# GD32M53x register map
File version: 1.0
CPU: CM33 r2p1, little endian, MPU, FPU, DSP, 4 interrupt priority bits
Registers are 32-bit, read-write, reset 0x0 unless marked. A register's access mark holds for its fields unless they carry their own. Offsets are from the block's base; [hi:lo] are bit positions; {n}, {i} and the like mark numbered series.

## RCU — Reset and clock unit
Base 0x40021000
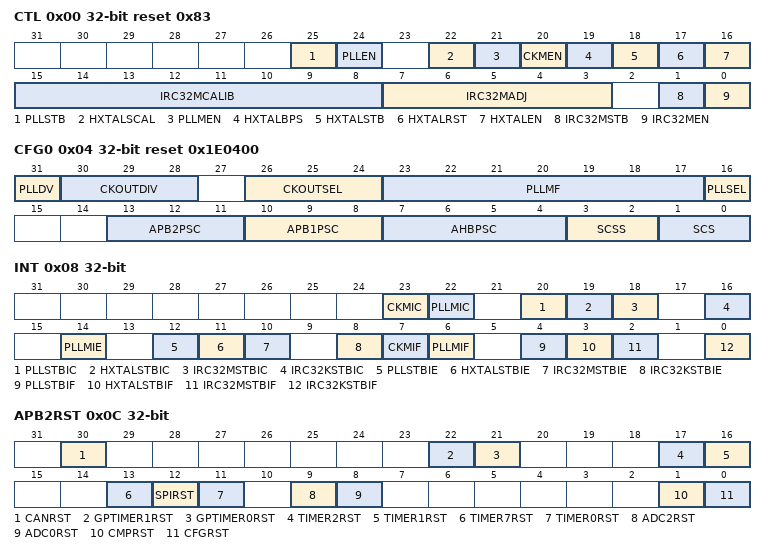
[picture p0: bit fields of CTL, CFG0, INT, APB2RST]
0x00 CTL access per field reset 0x83 — Control register
  [25] PLLSTB ro — PLL clock stabilization flag
  [24] PLLEN rw — PLL enable
  [22] HXTALSCAL rw — HXTAL frequency scale select
  [21] PLLMEN rw — PLL clock monitor enable
  [20] CKMEN rw — HXTAL clock monitor enable
  [19] HXTALBPS rw — External crystal oscillator (HXTAL) clock bypass mode enable
  [18] HXTALSTB ro — External crystal oscillator (HXTAL) clock stabilization flag
  [17] HXTALRST rw — External high speed oscillator ready reset
  [16] HXTALEN rw — External high speed oscillator enable
  [15:8] IRC32MCALIB ro — Internal 32M RC oscillator calibration value register
  [7:3] IRC32MADJ rw — Internal 32M RC oscillator clock trim adjust value
  [1] IRC32MSTB ro — IRC32M high speed internal oscillator stabilization flag
  [0] IRC32MEN rw — Internal high speed oscillator enable
0x04 CFG0 access per field reset 0x1E0400 — Configuration register 0
  [31] PLLDV rw — The CK_PLL divide by 1 or 8 for CK_OUT
  [30:28] CKOUTDIV rw — The CK_OUT divider which the CK_OUT frequency can be reduced, see bits 26:24 of RCU_CFG0 for CK_OUT.
  [26:24] CKOUTSEL rw — CK_OUT clock source selection
  [23:17] PLLMF rw — PLL multiply factor
  [16] PLLSEL rw — PLL clock source selection
  [13:11] APB2PSC rw — APB2 prescaler selection
  [10:8] APB1PSC rw — APB1 prescaler selection
  [7:4] AHBPSC rw — AHB prescaler selection
  [3:2] SCSS ro — System clock switch status
  [1:0] SCS rw — System clock switch
0x08 INT access per field — Interrupt register
  [23] CKMIC wo — HXTAL clock stuck interrupt clear
  [22] PLLMIC wo — PLL clock monitor interrupt clear
  [20] PLLSTBIC wo — PLL stabilization interrupt clear
  [19] HXTALSTBIC wo — HXTAL stabilization interrupt clear
  [18] IRC32MSTBIC wo — IRC32M stabilization interrupt clear
  [16] IRC32KSTBIC wo — IRC32K stabilization interrupt clear
  [14] PLLMIE rw — PLL clock monitor interrupt enable
  [12] PLLSTBIE rw — PLL stabilization interrupt enable
  [11] HXTALSTBIE rw — HXTAL stabilization interrupt enable
  [10] IRC32MSTBIE rw — IRC32M stabilization interrupt enable
  [8] IRC32KSTBIE rw — IRC32K stabilization interrupt enable
  [7] CKMIF ro — HXTAL clock stuck interrupt flag
  [6] PLLMIF ro — PLL clock monitor interrupt flag
  [4] PLLSTBIF ro — PLL stabilization interrupt flag
  [3] HXTALSTBIF ro — HXTAL stabilization interrupt flag
  [2] IRC32MSTBIF ro — IRC32M stabilization interrupt flag
  [0] IRC32KSTBIF ro — IRC32K stabilization interrupt flag
0x0C APB2RST — APB2 reset register
  [30] CANRST — CAN reset
  [22] GPTIMER1RST — GPTIMER1 reset
  [21] GPTIMER0RST — GPTIMER0 reset
  [17] TIMER2RST — TIMER2 reset
  [16] TIMER1RST — TIMER1 reset
  [13] TIMER7RST — TIMER7 reset
  [12] SPIRST — SPI reset
  [11] TIMER0RST — TIMER0 reset
  [9] ADC2RST — ADC2 reset
  [8] ADC0RST — ADC0 reset
  [1] CMPRST — Comparator reset
  [0] CFGRST — System configuration reset
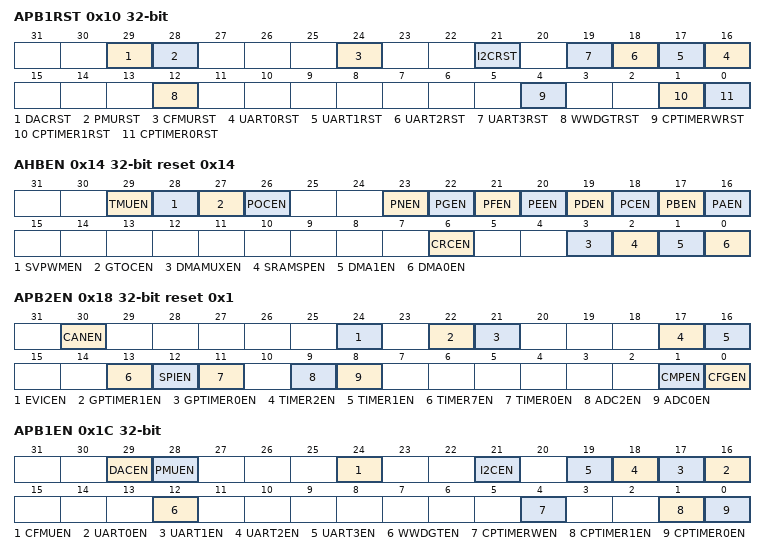
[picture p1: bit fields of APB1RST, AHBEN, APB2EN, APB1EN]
0x10 APB1RST — APB1 reset register
  [29] DACRST — DAC reset
  [28] PMURST — Power control reset
  [24] CFMURST — CFMU reset
  [21] I2CRST — I2C reset
  [n+16] UART{n}RST (n=0..3) — UART{n} reset
  [12] WWDGTRST — Window watchdog timer reset
  [4] CPTIMERWRST — CPTIMERW timer reset
  [1] CPTIMER1RST — CPTIMER1 timer reset
  [0] CPTIMER0RST — CPTIMER0 timer reset
0x14 AHBEN reset 0x14 — AHB enable register
  [29] TMUEN — TMU clock enable
  [28] SVPWMEN — SVPWM clock enable
  [27] GTOCEN — GTOC clock enable
  [26] POCEN — POC clock enable
  [23] PNEN — GPIO port N clock enable
  [22] PGEN — GPIO port G clock enable
  [21] PFEN — GPIO port F clock enable
  [20] PEEN — GPIO port E clock enable
  [19] PDEN — GPIO port D clock enable
  [18] PCEN — GPIO port C clock enable
  [17] PBEN — GPIO port B clock enable
  [16] PAEN — GPIO port A clock enable
  [6] CRCEN — CRC clock enable
  [3] DMAMUXEN — DMAMUX clock enable
  [2] SRAMSPEN — SRAM interface clock enable
  [1] DMA1EN — DMA1 clock enable
  [0] DMA0EN — DMA0 clock enable
0x18 APB2EN reset 0x1 — APB2 enable register
  [30] CANEN — CAN clock enable
  [24] EVICEN — EVIC clock enable
  [22] GPTIMER1EN — GPTIMER1 timer clock enable
  [21] GPTIMER0EN — GPTIMER0 timer clock enable
  [17] TIMER2EN — TIMER2 timer clock enable
  [16] TIMER1EN — TIMER1 timer clock enable
  [13] TIMER7EN — TIMER7 timer clock enable
  [12] SPIEN — SPI clock enable
  [11] TIMER0EN — TIMER0 timer clock enable
  [9] ADC2EN — ADC2 interface clock enable
  [8] ADC0EN — ADC interface clock enable
  [1] CMPEN — Comparator clock enable
  [0] CFGEN — System configuration clock enable
0x1C APB1EN — APB1 enable register
  [29] DACEN — DAC clock enable
  [28] PMUEN — Power interface clock enable
  [24] CFMUEN — CFMU clock enable
  [21] I2CEN — I2C clock enable
  [n+16] UART{n}EN (n=0..3) — UART{n} clock enable
  [12] WWDGTEN — Window watchdog timer clock enable
  [4] CPTIMERWEN — CPTIMERW timer clock enable
  [1] CPTIMER1EN — CPTIMER1 timer clock enable
  [0] CPTIMER0EN — CPTIMER0 timer clock enable
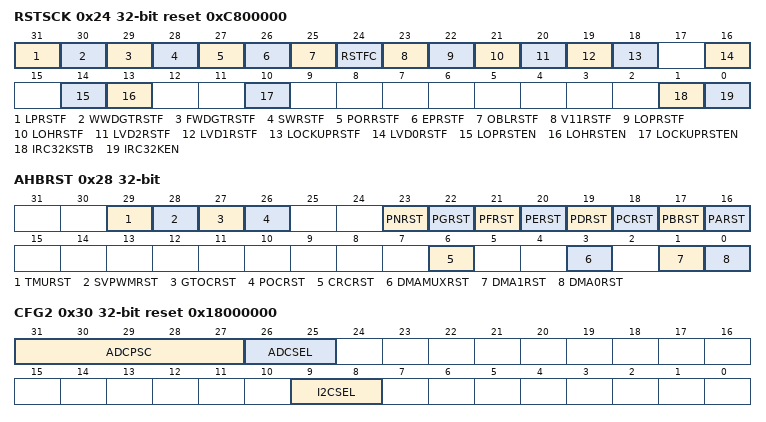
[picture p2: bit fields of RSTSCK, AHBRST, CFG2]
0x24 RSTSCK access per field reset 0xC800000 — Reset source/clock register
  [31] LPRSTF ro — Low-power reset flag
  [30] WWDGTRSTF ro — Window watchdog timer reset flag
  [29] FWDGTRSTF ro — Free Watchdog timer reset flag
  [28] SWRSTF ro — Software reset flag
  [27] PORRSTF ro — Power reset flag
  [26] EPRSTF ro — External PIN reset flag
  [25] OBLRSTF ro — Option byte loader reset flag
  [24] RSTFC rw — Reset flag clear
  [23] V11RSTF ro — 1.1V domain power reset flag
  [22] LOPRSTF ro — Lost of PLL error reset flag
  [21] LOHRSTF ro — Lost of HXTAL error reset flag
  [20] LVD2RSTF ro — Low voltage 2 detect error reset flag
  [19] LVD1RSTF ro — Low voltage 1 detect error reset flag
  [18] LOCKUPRSTF ro — CPU Lock-Up error reset flag
  [16] LVD0RSTF ro — Low voltage 0 detect error reset flag
  [14] LOPRSTEN rw — Lost of PLL reset enable
  [13] LOHRSTEN rw — Lost of HXTAL reset enable
  [10] LOCKUPRSTEN rw — CPU Lock-Up reset enable
  [1] IRC32KSTB ro — IRC32K stabilization
  [0] IRC32KEN rw — IRC32K enable
0x28 AHBRST — AHB reset register
  [29] TMURST — TMU reset
  [28] SVPWMRST — SVPWM reset
  [27] GTOCRST — GTOC reset
  [26] POCRST — POC reset
  [23] PNRST — GPIO port N reset
  [22] PGRST — GPIO port G reset
  [21] PFRST — GPIO port F reset
  [20] PERST — GPIO port E reset
  [19] PDRST — GPIO port D reset
  [18] PCRST — GPIO port C reset
  [17] PBRST — GPIO port B reset
  [16] PARST — GPIO port A reset
  [6] CRCRST — CRC reset
  [3] DMAMUXRST — DMAMUX reset
  [1] DMA1RST — DMA1 reset
  [0] DMA0RST — DMA0 reset
0x2C CFG1 — Configuration register 1
  [2:0] PREDV — CK_HXTAL divider previous PLL
0x30 CFG2 reset 0x18000000 — Configuration register 2
  [31:27] ADCPSC — ADC clock prescaler selection
  [26:25] ADCSEL — CK_ADCPRE clock source selection
  [9:8] I2CSEL — CK_I2C clock source selection
